# SF32LB58x register map
File version: 1.0
CPU: CM33 r0p1, little endian, MPU, FPU, 3 interrupt priority bits
Registers are 32-bit, read-write, reset 0x0 unless marked. A register's access mark holds for its fields unless they carry their own. Offsets are from the block's base; [hi:lo] are bit positions; {n}, {i} and the like mark numbered series.

## PMUC
Base 0x5004A000
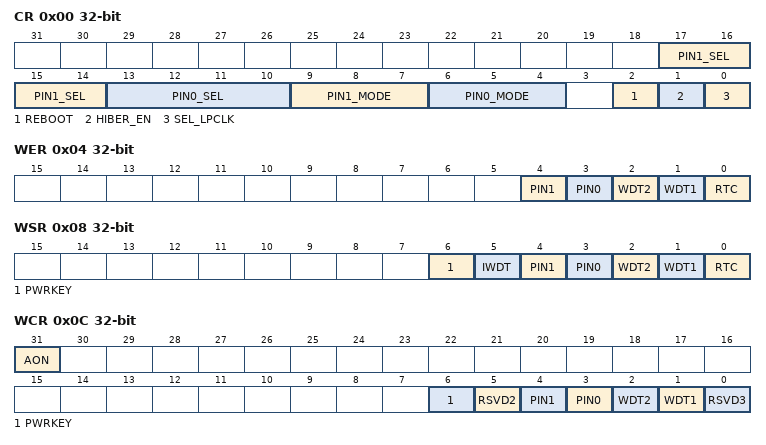
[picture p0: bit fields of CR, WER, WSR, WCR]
0x00 CR — Control Register
  [17:14] PIN1_SEL
  [13:10] PIN0_SEL — select one out of 16 Pins {PBR[3:0], PA[5:0], PB[5:0]}
  [9:7] PIN1_MODE — 0 - high level, 1 - low level, 2 - pos edge, 3 - neg edge
  [6:4] PIN0_MODE — 4/6 - both edge (high-active detection), 5/7 - both edge (low-active detection)
  [2] REBOOT — Write 1 to reboot; write 0 to clear after boot up
  [1] HIBER_EN — Write 1 to enter hibernate mode; write 0 to clear when exit from hibernate
  [0] SEL_LPCLK — 0 - LRC10, 1 - LXT32
0x04 WER — Wakeup Enable register
  [4] PIN1 — Set 1 to enable PIN1 as wakeup source
  [3] PIN0 — Set 1 to enable PIN0 as wakeup source
  [2] WDT2 — Set 1 to enable WDT2 as reboot cause
  [1] WDT1 — Set 1 to enable WDT1 as reboot cause
  [0] RTC — Set 1 to enable RTC as wakeup source
0x08 WSR — Wakeup Status register
  [6] PWRKEY
  [5] IWDT
  [4] PIN1
  [3] PIN0
  [2] WDT2 — Indicates reboot by WDT2
  [1] WDT1 — Indicates reboot by WDT1
  [0] RTC — Indicates the wakeup status from RTC. Note: the status is masked by WER
0x0C WCR — Wakeup Clear register
  [31] AON — Write 1 to clear the AON wakeup IRQ status
  [6] PWRKEY — Write 1 to clear PWRKEY reset flag
  [5] RSVD2 — Clear status in IWDT
  [4] PIN1 — Write 1 to clear PIN1 wakeup flag.
  [3] PIN0 — Write 1 to clear PIN0 wakeup flag. Only valid if PIN wakeup is configured as edge trigger
  [2] WDT2 — Write 1 to clear WDT2 reboot flag
  [1] WDT1 — Write 1 to clear WDT1 reboot flag
  [0] RSVD3 — Clear status in RTC
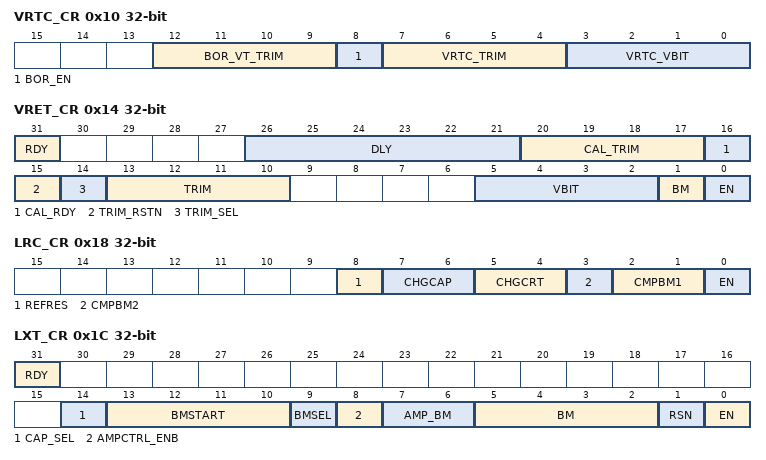
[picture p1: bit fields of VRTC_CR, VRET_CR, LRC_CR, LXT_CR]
0x10 VRTC_CR — VRTC Control Register
  [12:9] BOR_VT_TRIM
  [8] BOR_EN — Brownout Reset Enable
  [7:4] VRTC_TRIM
  [3:0] VRTC_VBIT
0x14 VRET_CR — VRET Control Register
  [31] RDY
  [26:21] DLY — VRET_LDO power up delay in number of CLK_LP cycles
  [20:17] CAL_TRIM
  [16] CAL_RDY
  [15] TRIM_RSTN
  [14] TRIM_SEL
  [13:10] TRIM
  [5:2] VBIT
  [1] BM
  [0] EN
0x18 LRC_CR — RC10K Control Register
  [8] REFRES
  [7:6] CHGCAP
  [5:4] CHGCRT
  [3] CMPBM2
  [2:1] CMPBM1
  [0] EN — Enabled by default
0x1C LXT_CR — XTAL32K Control Register
  [31] RDY, [14] CAP_SEL, [13:10] BMSTART, [9] BMSEL, [8] AMPCTRL_ENB, [7:6] AMP_BM, [5:2] BM, [1] RSN, [0] EN
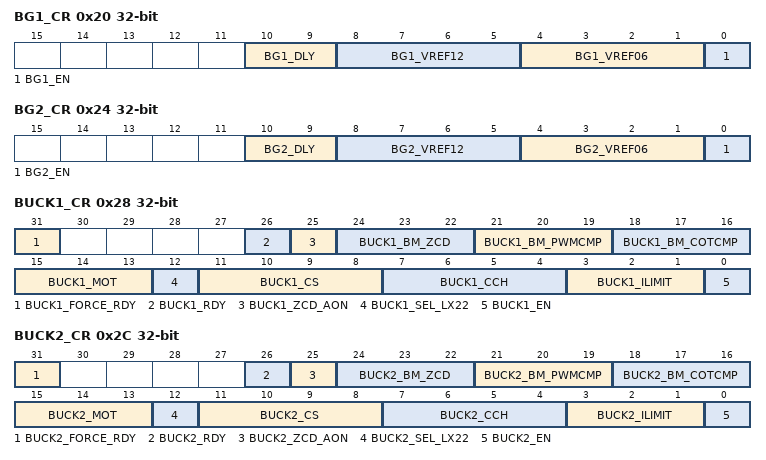
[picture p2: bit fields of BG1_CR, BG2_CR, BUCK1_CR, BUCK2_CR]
0x20 BG1_CR — BG1 Control Register
  [10:9] BG1_DLY — Bandgap power up delay in CLK_LP cycles
  [8:5] BG1_VREF12
  [4:1] BG1_VREF06
  [0] BG1_EN — Force BG1 enable
0x24 BG2_CR — BG2 Control Register
  [10:9] BG2_DLY — Bandgap power up delay in CLK_LP cycles
  [8:5] BG2_VREF12
  [4:1] BG2_VREF06
  [0] BG2_EN — Force BG2 enable
0x28 BUCK1_CR — BUCK1 Control Register 1
  [31] BUCK1_FORCE_RDY, [26] BUCK1_RDY, [25] BUCK1_ZCD_AON, [24:22] BUCK1_BM_ZCD, [21:19] BUCK1_BM_PWMCMP, [18:16] BUCK1_BM_COTCMP, [15:13] BUCK1_MOT, [12] BUCK1_SEL_LX22, [11:8] BUCK1_CS, [7:4] BUCK1_CCH, [3:1] BUCK1_ILIMIT, [0] BUCK1_EN
0x2C BUCK2_CR — BUCK2 Control Register 1
  [31] BUCK2_FORCE_RDY, [26] BUCK2_RDY, [25] BUCK2_ZCD_AON, [24:22] BUCK2_BM_ZCD, [21:19] BUCK2_BM_PWMCMP, [18:16] BUCK2_BM_COTCMP, [15:13] BUCK2_MOT, [12] BUCK2_SEL_LX22, [11:8] BUCK2_CS, [7:4] BUCK2_CCH, [3:1] BUCK2_ILIMIT, [0] BUCK2_EN
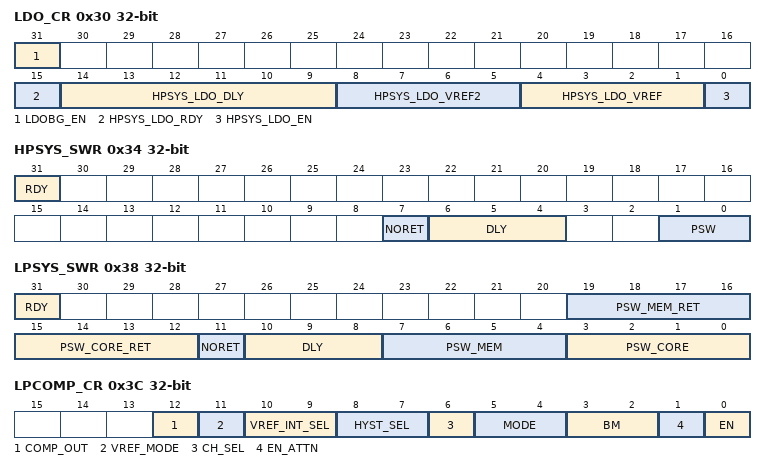
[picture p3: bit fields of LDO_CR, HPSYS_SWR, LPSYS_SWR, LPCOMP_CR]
0x30 LDO_CR — LDO Control Register
  [31] LDOBG_EN — Force LDOBG enable
  [15] HPSYS_LDO_RDY
  [14:9] HPSYS_LDO_DLY — HPSYS_LDO power up delay in CLK_LP cycles
  [8:5] HPSYS_LDO_VREF2 — Lower voltage if needed, selected by HPSYS AON
  [4:1] HPSYS_LDO_VREF
  [0] HPSYS_LDO_EN
0x34 HPSYS_SWR — HPSYS Switch Register
  [31] RDY
  [7] NORET — Cut off power switch entirely during standby. No retention
  [6:4] DLY — wait for N cycles before asserting RDY
  [1:0] PSW — [0] - RET_LDO; [1] - HPSYS_LDO
0x38 LPSYS_SWR — LPSYS Switch Register
  [31] RDY
  [19:16] PSW_MEM_RET — VLPMEM PSW value during retention (including deep sleep and standby)
  [15:12] PSW_CORE_RET — VLP core PSW value during retention (deep sleep)
  [11] NORET — Cut off VLPMEM power switch entirely during standby. No retention
  [10:8] DLY
  [7:4] PSW_MEM — [0] - RET_LDO; [1] - BUCK2; [2] - RSVD; [3] - SIMO VOUT2
  [3:0] PSW_CORE — [0] - RET_LDO; [1] - BUCK2; [2] - SIMO VOUT2; [3] - SIMO VOUT1
0x3C LPCOMP_CR — LPCOMP Control Register
  [12] COMP_OUT, [11] VREF_MODE, [10:9] VREF_INT_SEL, [8:7] HYST_SEL, [6] CH_SEL, [5:4] MODE, [3:2] BM, [1] EN_ATTN, [0] EN
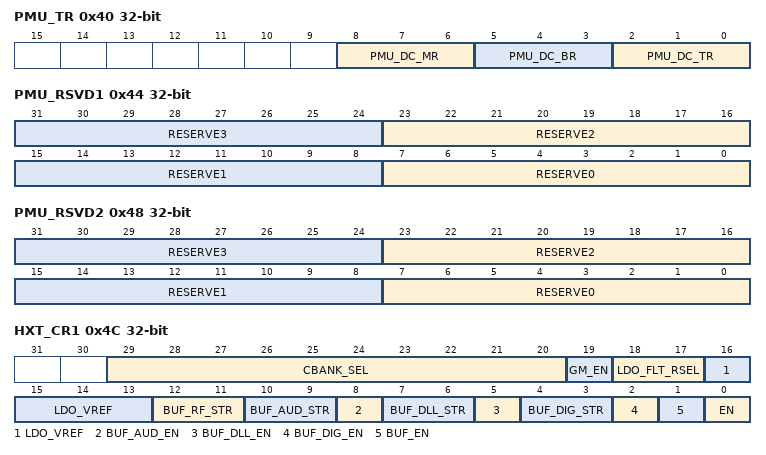
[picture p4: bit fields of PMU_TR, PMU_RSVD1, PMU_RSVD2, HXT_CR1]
0x40 PMU_TR — PMU Test Register
  [8:6] PMU_DC_MR — macro select
  [5:3] PMU_DC_BR — block select
  [2:0] PMU_DC_TR — test point select
0x44 PMU_RSVD1 — PMU Reserved Register 1
  [8n+7:8n] RESERVE{n} (n=0..3)
0x48 PMU_RSVD2 — PMU Reserved Register 2
  [8n+7:8n] RESERVE{n} (n=0..3)
0x4C HXT_CR1 — HXT48 Control Register 1
  [29:20] CBANK_SEL, [19] GM_EN, [18:17] LDO_FLT_RSEL, [16:13] LDO_VREF, [12:11] BUF_RF_STR, [10:9] BUF_AUD_STR, [8] BUF_AUD_EN, [7:6] BUF_DLL_STR, [5] BUF_DLL_EN, [4:3] BUF_DIG_STR, [2] BUF_DIG_EN, [1] BUF_EN, [0] EN
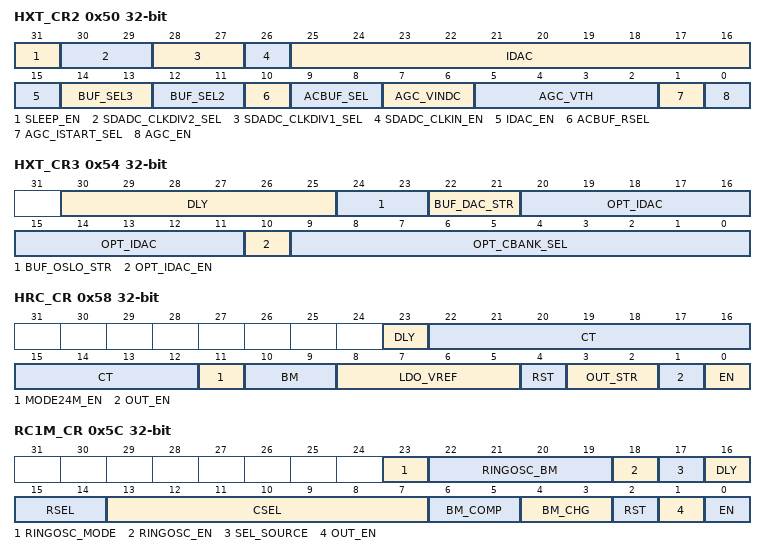
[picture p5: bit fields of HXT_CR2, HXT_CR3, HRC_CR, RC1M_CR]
0x50 HXT_CR2 — HXT48 Control Register 2
  [31] SLEEP_EN, [30:29] SDADC_CLKDIV2_SEL, [28:27] SDADC_CLKDIV1_SEL, [26] SDADC_CLKIN_EN, [25:16] IDAC, [15] IDAC_EN, [14:13] BUF_SEL3, [12:11] BUF_SEL2, [10] ACBUF_RSEL, [9:8] ACBUF_SEL, [7:6] AGC_VINDC, [5:2] AGC_VTH, [1] AGC_ISTART_SEL, [0] AGC_EN
0x54 HXT_CR3 — HXT48 Control Register 3
  [30:25] DLY, [24:23] BUF_OSLO_STR, [22:21] BUF_DAC_STR, [20:11] OPT_IDAC, [10] OPT_IDAC_EN, [9:0] OPT_CBANK_SEL
0x58 HRC_CR — HRC48 Control Register
  [23] DLY — number of cycles for BG ready. 0 - one cycle of CLK_LP; 1 - two cycles of CLK_LP
  [22:12] CT
  [11] MODE24M_EN
  [10:9] BM
  [8:5] LDO_VREF
  [4] RST
  [3:2] OUT_STR
  [1] OUT_EN
  [0] EN
0x5C RC1M_CR — RC1M Control Register
  [23] RINGOSC_MODE
  [22:19] RINGOSC_BM
  [18] RINGOSC_EN
  [17] SEL_SOURCE
  [16] DLY — number of cycles for BG ready. 0 - one cycle of CLK_LP; 1 - two cycles of CLK_LP
  [15:14] RSEL
  [13:7] CSEL
  [6:5] BM_COMP
  [4:3] BM_CHG
  [2] RST
  [1] OUT_EN
  [0] EN
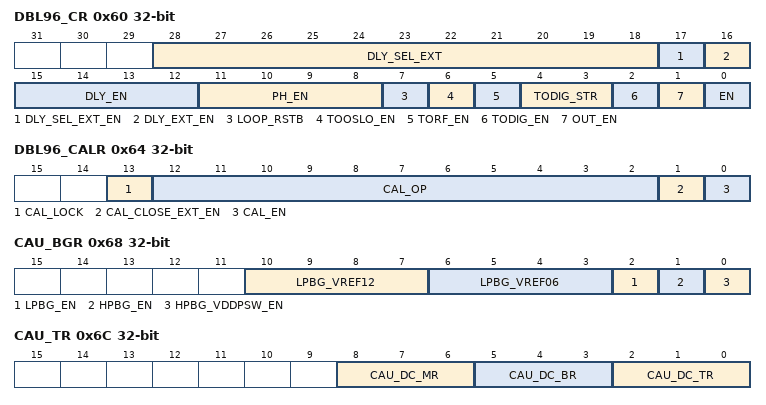
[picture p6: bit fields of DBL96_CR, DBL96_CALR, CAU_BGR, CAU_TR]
0x60 DBL96_CR — DBL96 Control Register
  [28:18] DLY_SEL_EXT, [17] DLY_SEL_EXT_EN, [16] DLY_EXT_EN, [15:12] DLY_EN, [11:8] PH_EN, [7] LOOP_RSTB, [6] TOOSLO_EN, [5] TORF_EN, [4:3] TODIG_STR, [2] TODIG_EN, [1] OUT_EN, [0] EN
0x64 DBL96_CALR — DBL96 Calibration Register
  [13] CAL_LOCK, [12:2] CAL_OP, [1] CAL_CLOSE_EXT_EN, [0] CAL_EN
0x68 CAU_BGR — CAU Bandgap Register
  [10:7] LPBG_VREF12, [6:3] LPBG_VREF06, [2] LPBG_EN, [1] HPBG_EN, [0] HPBG_VDDPSW_EN
0x6C CAU_TR — CAU Test Register
  [8:6] CAU_DC_MR, [5:3] CAU_DC_BR, [2:0] CAU_DC_TR
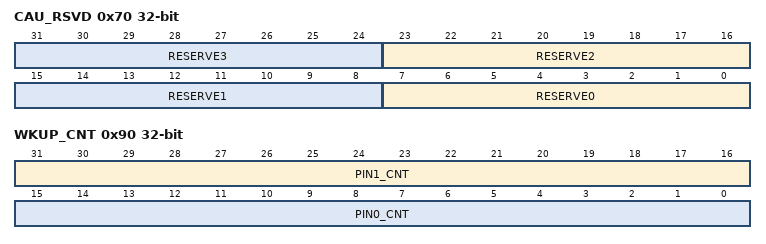
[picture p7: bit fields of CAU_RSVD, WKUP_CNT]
0x70 CAU_RSVD — CAU Reserved Register
  [8n+7:8n] RESERVE{n} (n=0..3)
0x90 WKUP_CNT — Wakeup Count Register
  [31:16] PIN1_CNT, [15:0] PIN0_CNT
